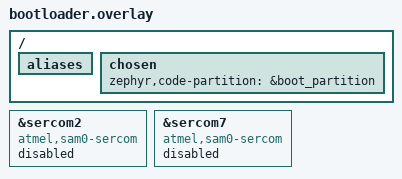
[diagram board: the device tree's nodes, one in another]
/ {
    /delete-node/ qspi-nor-flash@42003400;

    aliases {
        /delete-property/ sdhc0;
    };

    chosen {
        zephyr,code-partition = &boot_partition;
    };
};

&sercom2 {
    compatible = "atmel,sam0-sercom";
    status = "disabled";
    /delete-property/ dipo;
    /delete-property/ dopo;
    /delete-property/ cs-gpios;
    /delete-property/ pinctrl-0;
    /delete-property/ pinctrl-names;
    /delete-property/ #address-cells;
    /delete-property/ #size-cells;

    /delete-node/ sdhc@0;
};

&sercom7 {
    compatible = "atmel,sam0-sercom";
    status = "disabled";
    /delete-property/ dipo;
    /delete-property/ dopo;
    /delete-property/ pinctrl-0;
    /delete-property/ pinctrl-names;
};
